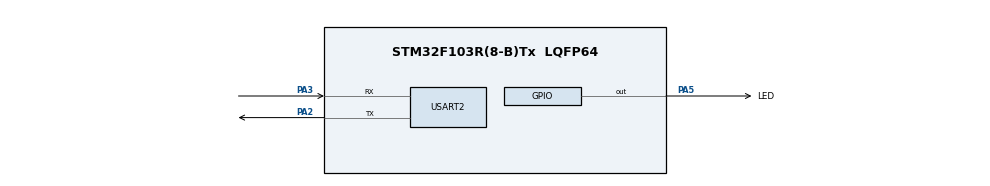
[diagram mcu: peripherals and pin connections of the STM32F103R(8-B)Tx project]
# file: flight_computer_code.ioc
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FREERTOS.Tasks01=turnLedOn,0,128,StartTurnLedOn,Default,NULL,Dynamic,NULL,NULL;turnLedOff,-1,128,StartTurnLedOff,Default,NULL,Dynamic,NULL,NULL
Mcu.Family=STM32F1
Mcu.Name=STM32F103R(8-B)Tx
Mcu.Package=LQFP64
NVIC.PriorityGroup=NVIC_PRIORITYGROUP_4
NVIC.TIM1_UP_IRQn=true\:15\:0\:false\:false\:true\:false\:false\:true\:true
NVIC.TimeBase=TIM1_UP_IRQn
NVIC.TimeBaseIP=TIM1
PA13.Mode=Serial_Wire
PA13.Signal=SYS_JTMS-SWDIO
PA14.Mode=Serial_Wire
PA14.Signal=SYS_JTCK-SWCLK
PA2.Mode=Asynchronous
PA2.Signal=USART2_TX
PA3.Mode=Asynchronous
PA3.Signal=USART2_RX
PA5.GPIO_Label=LED
PA5.Signal=GPIO_Output
ProjectManager.HeapSize=0x200
ProjectManager.StackSize=0x400
ProjectManager.TargetToolchain=STM32CubeIDE
RCC.APB1Freq_Value=8000000
RCC.APB2Freq_Value=8000000
USART2.Parity=PARITY_EVEN
USART2.VirtualMode=VM_ASYNC
VP_FREERTOS_VS_CMSIS_V1.Mode=CMSIS_V1
VP_SYS_VS_tim1.Mode=TIM1
board=custom

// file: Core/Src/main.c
/* USER CODE BEGIN Header */
/**
  ******************************************************************************
  * @file           : main.c
  * @brief          : Main program body
  ******************************************************************************
  * @attention
  *
  * Copyright (c) 2023 STMicroelectronics.
  * All rights reserved.
  *
  * This software is licensed under terms that can be found in the LICENSE file
  * in the root directory of this software component.
  * If no LICENSE file comes with this software, it is provided AS-IS.
  *
  ******************************************************************************
  */
/* USER CODE END Header */
#include "main.h"
#include "cmsis_os.h"

/* USER CODE BEGIN Includes */

#include "debug_printer/debug_printer.h"
/* USER CODE END Includes */

UART_HandleTypeDef huart2;

osThreadId turnLedOnHandle;
osThreadId turnLedOffHandle;

void SystemClock_Config(void);
static void MX_GPIO_Init(void);
static void MX_USART2_UART_Init(void);
void StartTurnLedOn(void const * argument);
void StartTurnLedOff(void const * argument);

int main(void)
{

  /* MCU Configuration--------------------------------------------------------*/

  /* Reset of all peripherals, Initializes the Flash interface and the Systick. */
  HAL_Init();

  /* Configure the system clock */
  SystemClock_Config();

  /* Initialize all configured peripherals */
  MX_GPIO_Init();
  MX_USART2_UART_Init();
  /* USER CODE BEGIN 2 */
  uart_init(huart2);
  /* USER CODE END 2 */

  /* Create the thread(s) */
  /* definition and creation of turnLedOn */
  osThreadDef(turnLedOn, StartTurnLedOn, osPriorityNormal, 0, 128);
  turnLedOnHandle = osThreadCreate(osThread(turnLedOn), NULL);

  /* definition and creation of turnLedOff */
  osThreadDef(turnLedOff, StartTurnLedOff, osPriorityBelowNormal, 0, 128);
  turnLedOffHandle = osThreadCreate(osThread(turnLedOff), NULL);

  /* Start scheduler */
  osKernelStart();
  /* We should never get here as control is now taken by the scheduler */
  /* Infinite loop */
  while (1)
  {

  }
}

void SystemClock_Config(void)
{
  RCC_OscInitTypeDef RCC_OscInitStruct = {0};
  RCC_ClkInitTypeDef RCC_ClkInitStruct = {0};

  /** Initializes the RCC Oscillators according to the specified parameters
  * in the RCC_OscInitTypeDef structure.
  */
  RCC_OscInitStruct.OscillatorType = RCC_OSCILLATORTYPE_HSI;
  RCC_OscInitStruct.HSIState = RCC_HSI_ON;
  RCC_OscInitStruct.HSICalibrationValue = RCC_HSICALIBRATION_DEFAULT;
  RCC_OscInitStruct.PLL.PLLState = RCC_PLL_NONE;
  if (HAL_RCC_OscConfig(&RCC_OscInitStruct) != HAL_OK)
  {
    Error_Handler();
  }

  /** Initializes the CPU, AHB and APB buses clocks
  */
  RCC_ClkInitStruct.ClockType = RCC_CLOCKTYPE_HCLK|RCC_CLOCKTYPE_SYSCLK
                              |RCC_CLOCKTYPE_PCLK1|RCC_CLOCKTYPE_PCLK2;
  RCC_ClkInitStruct.SYSCLKSource = RCC_SYSCLKSOURCE_HSI;
  RCC_ClkInitStruct.AHBCLKDivider = RCC_SYSCLK_DIV1;
  RCC_ClkInitStruct.APB1CLKDivider = RCC_HCLK_DIV1;
  RCC_ClkInitStruct.APB2CLKDivider = RCC_HCLK_DIV1;

  if (HAL_RCC_ClockConfig(&RCC_ClkInitStruct, FLASH_LATENCY_0) != HAL_OK)
  {
    Error_Handler();
  }
}

static void MX_USART2_UART_Init(void)
{

  huart2.Instance = USART2;
  huart2.Init.BaudRate = 115200;
  huart2.Init.WordLength = UART_WORDLENGTH_8B;
  huart2.Init.StopBits = UART_STOPBITS_1;
  huart2.Init.Parity = UART_PARITY_EVEN;
  huart2.Init.Mode = UART_MODE_TX_RX;
  huart2.Init.HwFlowCtl = UART_HWCONTROL_NONE;
  huart2.Init.OverSampling = UART_OVERSAMPLING_16;
  if (HAL_UART_Init(&huart2) != HAL_OK)
  {
    Error_Handler();
  }

}

static void MX_GPIO_Init(void)
{
  GPIO_InitTypeDef GPIO_InitStruct = {0};

  /* GPIO Ports Clock Enable */
  __HAL_RCC_GPIOA_CLK_ENABLE();

  /*Configure GPIO pin Output Level */
  HAL_GPIO_WritePin(LED_GPIO_Port, LED_Pin, GPIO_PIN_RESET);

  /*Configure GPIO pin : LED_Pin */
  GPIO_InitStruct.Pin = LED_Pin;
  GPIO_InitStruct.Mode = GPIO_MODE_OUTPUT_PP;
  GPIO_InitStruct.Pull = GPIO_NOPULL;
  GPIO_InitStruct.Speed = GPIO_SPEED_FREQ_LOW;
  HAL_GPIO_Init(LED_GPIO_Port, &GPIO_InitStruct);

}

void StartTurnLedOn(void const * argument)
{
  /* USER CODE BEGIN 5 */
  /* Infinite loop */
  for(;;)
  {
	// Turn led on
	HAL_GPIO_WritePin(GPIOA, LED_Pin, GPIO_PIN_SET);
//	if(HAL_UART_Transmit(&huart2, "ON!! ", 6, 100) != HAL_OK){
//		Error_Handler();
//	}

	debug_print("ON!! ");
    osDelay(1000);
  }
  /* USER CODE END 5 */
}

void StartTurnLedOff(void const * argument)
{
  /* USER CODE BEGIN StartTurnLedOff */
  /* Infinite loop */
  for(;;)
  {
	  // Turn Led off
	  HAL_GPIO_WritePin(GPIOA, LED_Pin, GPIO_PIN_RESET);
	  debug_print("OFF!! ");
	  osDelay(2000);
  }
  /* USER CODE END StartTurnLedOff */
}

void HAL_TIM_PeriodElapsedCallback(TIM_HandleTypeDef *htim)
{
  if (htim->Instance == TIM1) {
    HAL_IncTick();
  }
}

void Error_Handler(void)
{
  __disable_irq();
  while (1)
  {
  }
}
